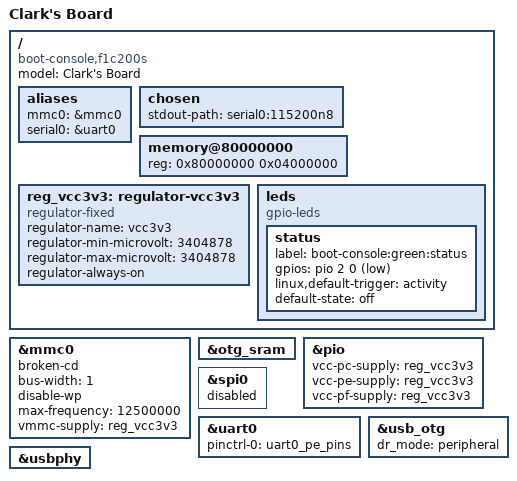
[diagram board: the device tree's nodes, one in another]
// SPDX-License-Identifier: (GPL-2.0+ OR MIT)
/dts-v1/;

#include "allwinner/suniv-f1c100s.dtsi"
#include <dt-bindings/gpio/gpio.h>

/ {
	model = "Clark's Board";
	compatible = "boot-console,f1c200s", "allwinner,suniv-f1c100s";

	aliases {
		mmc0 = &mmc0;
		serial0 = &uart0;
	};

	chosen {
		stdout-path = "serial0:115200n8";
	};

	memory@80000000 {
		device_type = "memory";
		reg = <0x80000000 0x04000000>;
	};

	reg_vcc3v3: regulator-vcc3v3 {
		compatible = "regulator-fixed";
		regulator-name = "vcc3v3";
		regulator-min-microvolt = <3404878>;
		regulator-max-microvolt = <3404878>;
		regulator-always-on;
	};

	leds {
		compatible = "gpio-leds";

		status {
			label = "boot-console:green:status";
			gpios = <&pio 2 0 GPIO_ACTIVE_LOW>;
			linux,default-trigger = "activity";
			default-state = "off";
		};
	};
};

&mmc0 {
	broken-cd;
	bus-width = <1>;
	disable-wp;
	max-frequency = <12500000>;
	vmmc-supply = <&reg_vcc3v3>;
	status = "okay";
};

&otg_sram {
	status = "okay";
};

&pio {
	vcc-pc-supply = <&reg_vcc3v3>;
	vcc-pe-supply = <&reg_vcc3v3>;
	vcc-pf-supply = <&reg_vcc3v3>;

	/delete-node/ spi0-pc-pins;
};

&spi0 {
	status = "disabled";
};

&uart0 {
	pinctrl-names = "default";
	pinctrl-0 = <&uart0_pe_pins>;
	status = "okay";
};

&usb_otg {
	dr_mode = "peripheral";
	status = "okay";
};

&usbphy {
	status = "okay";
};
